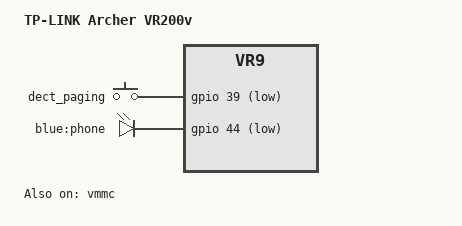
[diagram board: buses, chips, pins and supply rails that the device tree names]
#include "vr9_tplink_vr200.dtsi"

/ {
	compatible = "tplink,vr200v", "lantiq,xway", "lantiq,vr9";
	model = "TP-LINK Archer VR200v";

	chosen {
		bootargs = "console=ttyLTQ0,115200 mem=126M vpe1_load_addr=0x87e00000 vpe1_mem=2M maxvpes=1 maxtcs=1 nosmp";
	};
};

&keys {
	dect_paging {
		label = "dect_paging";
		gpios = <&gpio 39 GPIO_ACTIVE_LOW>;
		linux,code = <KEY_PHONE>;
	};
};

&leds {
	phone {
		label = "blue:phone";
		gpios = <&gpio 44 GPIO_ACTIVE_LOW>;
	};
};

&vmmc {
	status = "okay";
	gpios = <&gpio 30 GPIO_ACTIVE_HIGH  //fxs relay
			 &gpio 31 GPIO_ACTIVE_HIGH  //still unknown
			 &gpio 3  GPIO_ACTIVE_HIGH>; //reset_slic?
};
